# MSPM0G350X register map
Vendor: Texas Instruments; File version: This preliminary header file does not have a version number - build date: 2023-02-21 16:25:48
CPU: CM0 r0p1, little endian, MPU, no FPU, 3 interrupt priority bits
Registers are 32-bit, read-write, reset 0x0 unless marked. A register's access mark holds for its fields unless they carry their own. Offsets are from the block's base; [hi:lo] are bit positions; {n}, {i} and the like mark numbered series.

## SYSCTL — mem_map
Base 0x400AF000
0x1020 IIDX ro — SYSCTL interrupt index
  [3:0] IIDX_STAT — The SYSCTL interrupt index (IIDX) register generates a value corresponding to the highest priority pending interrupt source. This value may be used as an address offset for fast, deterministic handling in the interrupt service routine. A read of the IIDX register will clear the corresponding interrupt status in the RIS and MIS registers.
    0=IIDX_STAT_NO_INTR (NO_INTR); 1=IIDX_STAT_LFOSCGOOD (LFOSCGOOD); 2=IIDX_STAT_ANACLKERR (ANACLKERR); 3=IIDX_STAT_FLASHSEC (FLASHSEC); 4=IIDX_STAT_SRAMSEC (SRAMSEC); 5=IIDX_STAT_LFXTGOOD (LFXTGOOD); 6=IIDX_STAT_HFCLKGOOD (HFCLKGOOD); 7=IIDX_STAT_SYSPLLGOOD (SYSPLLGOOD); 8=IIDX_STAT_HSCLKGOOD (HSCLKGOOD)
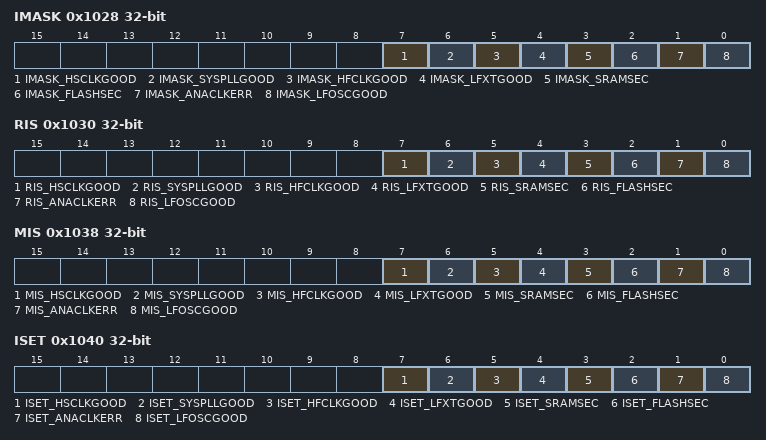
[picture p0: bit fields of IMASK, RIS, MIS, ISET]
0x1028 IMASK — SYSCTL interrupt mask
  [7] IMASK_HSCLKGOOD — HSCLK GOOD
    0=IMASK_HSCLKGOOD_DISABLE (DISABLE); 1=IMASK_HSCLKGOOD_ENABLE (ENABLE)
  [6] IMASK_SYSPLLGOOD — SYSPLL GOOD
    0=IMASK_SYSPLLGOOD_DISABLE (DISABLE); 1=IMASK_SYSPLLGOOD_ENABLE (ENABLE)
  [5] IMASK_HFCLKGOOD — HFCLK GOOD
    0=IMASK_HFCLKGOOD_DISABLE (DISABLE); 1=IMASK_HFCLKGOOD_ENABLE (ENABLE)
  [4] IMASK_LFXTGOOD — LFXT GOOD
    0=IMASK_LFXTGOOD_DISABLE (DISABLE); 1=IMASK_LFXTGOOD_ENABLE (ENABLE)
  [3] IMASK_SRAMSEC — SRAM Single Error Correct
    0=IMASK_SRAMSEC_DISABLE (DISABLE); 1=IMASK_SRAMSEC_ENABLE (ENABLE)
  [2] IMASK_FLASHSEC — Flash Single Error Correct
    0=IMASK_FLASHSEC_DISABLE (DISABLE); 1=IMASK_FLASHSEC_ENABLE (ENABLE)
  [1] IMASK_ANACLKERR — Analog Clocking Consistency Error
    0=IMASK_ANACLKERR_DISABLE (DISABLE); 1=IMASK_ANACLKERR_ENABLE (ENABLE)
  [0] IMASK_LFOSCGOOD — Enable or disable the LFOSCGOOD interrupt. LFOSCGOOD indicates that the LFOSC has started successfully.
    0=IMASK_LFOSCGOOD_DISABLE (DISABLE); 1=IMASK_LFOSCGOOD_ENABLE (ENABLE)
0x1030 RIS ro — SYSCTL raw interrupt status
  [7] RIS_HSCLKGOOD — HSCLK GOOD
    0=RIS_HSCLKGOOD_FALSE (FALSE); 1=RIS_HSCLKGOOD_TRUE (TRUE)
  [6] RIS_SYSPLLGOOD — SYSPLL GOOD
    0=RIS_SYSPLLGOOD_FALSE (FALSE); 1=RIS_SYSPLLGOOD_TRUE (TRUE)
  [5] RIS_HFCLKGOOD — HFCLK GOOD
    0=RIS_HFCLKGOOD_FALSE (FALSE); 1=RIS_HFCLKGOOD_TRUE (TRUE)
  [4] RIS_LFXTGOOD — LFXT GOOD
    0=RIS_LFXTGOOD_FALSE (FALSE); 1=RIS_LFXTGOOD_TRUE (TRUE)
  [3] RIS_SRAMSEC — SRAM Single Error Correct
    0=RIS_SRAMSEC_FALSE (FALSE); 1=RIS_SRAMSEC_TRUE (TRUE)
  [2] RIS_FLASHSEC — Flash Single Error Correct
    0=RIS_FLASHSEC_FALSE (FALSE); 1=RIS_FLASHSEC_TRUE (TRUE)
  [1] RIS_ANACLKERR — Analog Clocking Consistency Error
    0=RIS_ANACLKERR_FALSE (FALSE); 1=RIS_ANACLKERR_TRUE (TRUE)
  [0] RIS_LFOSCGOOD — Raw status of the LFOSCGOOD interrupt.
    0=RIS_LFOSCGOOD_FALSE (FALSE); 1=RIS_LFOSCGOOD_TRUE (TRUE)
0x1038 MIS ro — SYSCTL masked interrupt status
  [7] MIS_HSCLKGOOD — HSCLK GOOD
    0=MIS_HSCLKGOOD_FALSE (FALSE); 1=MIS_HSCLKGOOD_TRUE (TRUE)
  [6] MIS_SYSPLLGOOD — SYSPLL GOOD
    0=MIS_SYSPLLGOOD_FALSE (FALSE); 1=MIS_SYSPLLGOOD_TRUE (TRUE)
  [5] MIS_HFCLKGOOD — HFCLK GOOD
    0=MIS_HFCLKGOOD_FALSE (FALSE); 1=MIS_HFCLKGOOD_TRUE (TRUE)
  [4] MIS_LFXTGOOD — LFXT GOOD
    0=MIS_LFXTGOOD_FALSE (FALSE); 1=MIS_LFXTGOOD_TRUE (TRUE)
  [3] MIS_SRAMSEC — SRAM Single Error Correct
    0=MIS_SRAMSEC_FALSE (FALSE); 1=MIS_SRAMSEC_TRUE (TRUE)
  [2] MIS_FLASHSEC — Flash Single Error Correct
    0=MIS_FLASHSEC_FALSE (FALSE); 1=MIS_FLASHSEC_TRUE (TRUE)
  [1] MIS_ANACLKERR — Analog Clocking Consistency Error
    0=MIS_ANACLKERR_FALSE (FALSE); 1=MIS_ANACLKERR_TRUE (TRUE)
  [0] MIS_LFOSCGOOD — Masked status of the LFOSCGOOD interrupt.
    0=MIS_LFOSCGOOD_FALSE (FALSE); 1=MIS_LFOSCGOOD_TRUE (TRUE)
0x1040 ISET wo — SYSCTL interrupt set
  [7] ISET_HSCLKGOOD — HSCLK GOOD
    0=ISET_HSCLKGOOD_NO_EFFECT (NO_EFFECT); 1=ISET_HSCLKGOOD_SET (SET)
  [6] ISET_SYSPLLGOOD — SYSPLL GOOD
    0=ISET_SYSPLLGOOD_NO_EFFECT (NO_EFFECT); 1=ISET_SYSPLLGOOD_SET (SET)
  [5] ISET_HFCLKGOOD — HFCLK GOOD
    0=ISET_HFCLKGOOD_NO_EFFECT (NO_EFFECT); 1=ISET_HFCLKGOOD_SET (SET)
  [4] ISET_LFXTGOOD — LFXT GOOD
    0=ISET_LFXTGOOD_NO_EFFECT (NO_EFFECT); 1=ISET_LFXTGOOD_SET (SET)
  [3] ISET_SRAMSEC — SRAM Single Error Correct
    0=ISET_SRAMSEC_NO_EFFECT (NO_EFFECT); 1=ISET_SRAMSEC_SET (SET)
  [2] ISET_FLASHSEC — Flash Single Error Correct
    0=ISET_FLASHSEC_NO_EFFECT (NO_EFFECT); 1=ISET_FLASHSEC_SET (SET)
  [1] ISET_ANACLKERR — Analog Clocking Consistency Error
    0=ISET_ANACLKERR_NO_EFFECT (NO_EFFECT); 1=ISET_ANACLKERR_SET (SET)
  [0] ISET_LFOSCGOOD — Set the LFOSCGOOD interrupt.
    0=ISET_LFOSCGOOD_NO_EFFECT (NO_EFFECT); 1=ISET_LFOSCGOOD_SET (SET)
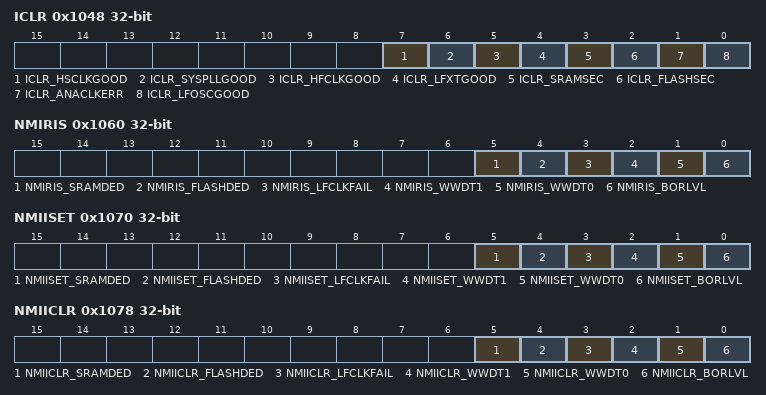
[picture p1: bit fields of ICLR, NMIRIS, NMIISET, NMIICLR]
0x1048 ICLR wo — SYSCTL interrupt clear
  [7] ICLR_HSCLKGOOD — HSCLK GOOD
    0=ICLR_HSCLKGOOD_NO_EFFECT (NO_EFFECT); 1=ICLR_HSCLKGOOD_CLR (CLR)
  [6] ICLR_SYSPLLGOOD — SYSPLL GOOD
    0=ICLR_SYSPLLGOOD_NO_EFFECT (NO_EFFECT); 1=ICLR_SYSPLLGOOD_CLR (CLR)
  [5] ICLR_HFCLKGOOD — HFCLK GOOD
    0=ICLR_HFCLKGOOD_NO_EFFECT (NO_EFFECT); 1=ICLR_HFCLKGOOD_CLR (CLR)
  [4] ICLR_LFXTGOOD — LFXT GOOD
    0=ICLR_LFXTGOOD_NO_EFFECT (NO_EFFECT); 1=ICLR_LFXTGOOD_CLR (CLR)
  [3] ICLR_SRAMSEC — SRAM Single Error Correct
    0=ICLR_SRAMSEC_NO_EFFECT (NO_EFFECT); 1=ICLR_SRAMSEC_CLR (CLR)
  [2] ICLR_FLASHSEC — Flash Single Error Correct
    0=ICLR_FLASHSEC_NO_EFFECT (NO_EFFECT); 1=ICLR_FLASHSEC_CLR (CLR)
  [1] ICLR_ANACLKERR — Analog Clocking Consistency Error
    0=ICLR_ANACLKERR_NO_EFFECT (NO_EFFECT); 1=ICLR_ANACLKERR_CLR (CLR)
  [0] ICLR_LFOSCGOOD — Clear the LFOSCGOOD interrupt.
    0=ICLR_LFOSCGOOD_NO_EFFECT (NO_EFFECT); 1=ICLR_LFOSCGOOD_CLR (CLR)
0x1050 NMIIIDX ro — NMI interrupt index
  [3:0] NMIIIDX_STAT — The NMI interrupt index (NMIIIDX) register generates a value corresponding to the highest priority pending NMI source. This value may be used as an address offset for fast, deterministic handling in the NMI service routine. A read of the NMIIIDX register will clear the corresponding interrupt status in the NMIRIS register.
    0=NMIIIDX_STAT_NO_INTR (NO_INTR); 1=NMIIIDX_STAT_BORLVL (BORLVL); 2=NMIIIDX_STAT_WWDT0 (WWDT0); 3=NMIIIDX_STAT_WWDT1 (WWDT1); 4=NMIIIDX_STAT_LFCLKFAIL (LFCLKFAIL); 5=NMIIIDX_STAT_FLASHDED (FLASHDED); 6=NMIIIDX_STAT_SRAMDED (SRAMDED)
0x1060 NMIRIS ro — NMI raw interrupt status
  [5] NMIRIS_SRAMDED — SRAM Double Error Detect
    0=NMIRIS_SRAMDED_FALSE (FALSE); 1=NMIRIS_SRAMDED_TRUE (TRUE)
  [4] NMIRIS_FLASHDED — Flash Double Error Detect
    0=NMIRIS_FLASHDED_FALSE (FALSE); 1=NMIRIS_FLASHDED_TRUE (TRUE)
  [3] NMIRIS_LFCLKFAIL — LFXT-EXLF Monitor Fail
    0=NMIRIS_LFCLKFAIL_FALSE (FALSE); 1=NMIRIS_LFCLKFAIL_TRUE (TRUE)
  [2] NMIRIS_WWDT1 — Watch Dog 0 Fault
    0=NMIRIS_WWDT1_FALSE (FALSE); 1=NMIRIS_WWDT1_TRUE (TRUE)
  [1] NMIRIS_WWDT0 — Watch Dog 0 Fault
    0=NMIRIS_WWDT0_FALSE (FALSE); 1=NMIRIS_WWDT0_TRUE (TRUE)
  [0] NMIRIS_BORLVL — Raw status of the BORLVL NMI
    0=NMIRIS_BORLVL_FALSE (FALSE); 1=NMIRIS_BORLVL_TRUE (TRUE)
0x1070 NMIISET wo — NMI interrupt set
  [5] NMIISET_SRAMDED — SRAM Double Error Detect
    0=NMIISET_SRAMDED_NO_EFFECT (NO_EFFECT); 1=NMIISET_SRAMDED_SET (SET)
  [4] NMIISET_FLASHDED — Flash Double Error Detect
    0=NMIISET_FLASHDED_NO_EFFECT (NO_EFFECT); 1=NMIISET_FLASHDED_SET (SET)
  [3] NMIISET_LFCLKFAIL — LFXT-EXLF Monitor Fail
    0=NMIISET_LFCLKFAIL_NO_EFFECT (NO_EFFECT); 1=NMIISET_LFCLKFAIL_SET (SET)
  [2] NMIISET_WWDT1 — Watch Dog 0 Fault
    0=NMIISET_WWDT1_NO_EFFECT (NO_EFFECT); 1=NMIISET_WWDT1_SET (SET)
  [1] NMIISET_WWDT0 — Watch Dog 0 Fault
    0=NMIISET_WWDT0_NO_EFFECT (NO_EFFECT); 1=NMIISET_WWDT0_SET (SET)
  [0] NMIISET_BORLVL — Set the BORLVL NMI
    0=NMIISET_BORLVL_NO_EFFECT (NO_EFFECT); 1=NMIISET_BORLVL_SET (SET)
0x1078 NMIICLR wo — NMI interrupt clear
  [5] NMIICLR_SRAMDED — SRAM Double Error Detect
    0=NMIICLR_SRAMDED_NO_EFFECT (NO_EFFECT); 1=NMIICLR_SRAMDED_CLR (CLR)
  [4] NMIICLR_FLASHDED — Flash Double Error Detect
    0=NMIICLR_FLASHDED_NO_EFFECT (NO_EFFECT); 1=NMIICLR_FLASHDED_CLR (CLR)
  [3] NMIICLR_LFCLKFAIL — LFXT-EXLF Monitor Fail
    0=NMIICLR_LFCLKFAIL_NO_EFFECT (NO_EFFECT); 1=NMIICLR_LFCLKFAIL_CLR (CLR)
  [2] NMIICLR_WWDT1 — Watch Dog 0 Fault
    0=NMIICLR_WWDT1_NO_EFFECT (NO_EFFECT); 1=NMIICLR_WWDT1_CLR (CLR)
  [1] NMIICLR_WWDT0 — Watch Dog 0 Fault
    0=NMIICLR_WWDT0_NO_EFFECT (NO_EFFECT); 1=NMIICLR_WWDT0_CLR (CLR)
  [0] NMIICLR_BORLVL — Clr the BORLVL NMI
    0=NMIICLR_BORLVL_NO_EFFECT (NO_EFFECT); 1=NMIICLR_BORLVL_CLR (CLR)
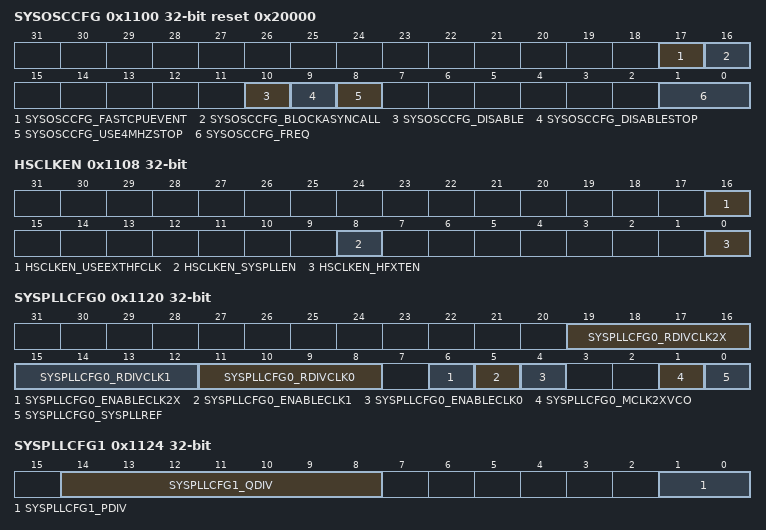
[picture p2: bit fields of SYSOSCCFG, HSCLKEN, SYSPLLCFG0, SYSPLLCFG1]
0x1100 SYSOSCCFG reset 0x20000 — SYSOSC configuration
  [17] SYSOSCCFG_FASTCPUEVENT — FASTCPUEVENT may be used to assert a fast clock request when an interrupt is asserted to the CPU, reducing interrupt latency.
    0=SYSOSCCFG_FASTCPUEVENT_DISABLE (DISABLE); 1=SYSOSCCFG_FASTCPUEVENT_ENABLE (ENABLE)
  [16] SYSOSCCFG_BLOCKASYNCALL — BLOCKASYNCALL may be used to mask block all asynchronous fast clock requests, preventing hardware from dynamically changing the active clock configuration when operating in a given mode.
    0=SYSOSCCFG_BLOCKASYNCALL_DISABLE (DISABLE); 1=SYSOSCCFG_BLOCKASYNCALL_ENABLE (ENABLE)
  [10] SYSOSCCFG_DISABLE — DISABLE sets the SYSOSC enable/disable policy. SYSOSC may be powered off in RUN, SLEEP, and STOP modes to reduce power consumption. When SYSOSC is disabled, MCLK and ULPCLK are sourced from LFCLK.
    0=SYSOSCCFG_DISABLE_DISABLE (DISABLE); 1=SYSOSCCFG_DISABLE_ENABLE (ENABLE)
  [9] SYSOSCCFG_DISABLESTOP — DISABLESTOP sets the SYSOSC stop mode enable/disable policy. When operating in STOP mode, the SYSOSC may be automatically disabled. When set, ULPCLK will run from LFCLK in STOP mode and SYSOSC will be disabled to reduce power consumption.
    0=SYSOSCCFG_DISABLESTOP_DISABLE (DISABLE); 1=SYSOSCCFG_DISABLESTOP_ENABLE (ENABLE)
  [8] SYSOSCCFG_USE4MHZSTOP — USE4MHZSTOP sets the SYSOSC stop mode frequency policy. When entering STOP mode, the SYSOSC frequency may be automatically switched to 4MHz to reduce SYSOSC power consumption.
    0=SYSOSCCFG_USE4MHZSTOP_DISABLE (DISABLE); 1=SYSOSCCFG_USE4MHZSTOP_ENABLE (ENABLE)
  [1:0] SYSOSCCFG_FREQ — Target operating frequency for the system oscillator (SYSOSC)
    0=SYSOSCCFG_FREQ_SYSOSCBASE (SYSOSCBASE); 1=SYSOSCCFG_FREQ_SYSOSC4M (SYSOSC4M); 2=SYSOSCCFG_FREQ_SYSOSCUSER (SYSOSCUSER)
0x1108 HSCLKEN — High-speed clock (HSCLK) source enable/disable
  [16] HSCLKEN_USEEXTHFCLK — USEEXTHFCLK selects the HFCLK_IN digital clock input to be the source for HFCLK. When disabled, HFXT is the HFCLK source and HFXTEN may be set. Do not set HFXTEN and USEEXTHFCLK simultaneously.
    0=HSCLKEN_USEEXTHFCLK_DISABLE (DISABLE); 1=HSCLKEN_USEEXTHFCLK_ENABLE (ENABLE)
  [8] HSCLKEN_SYSPLLEN — SYSPLLEN enables or disables the system phase-lock loop (SYSPLL).
    0=HSCLKEN_SYSPLLEN_DISABLE (DISABLE); 1=HSCLKEN_SYSPLLEN_ENABLE (ENABLE)
  [0] HSCLKEN_HFXTEN — HFXTEN enables or disables the high frequency crystal oscillator (HFXT).
    0=HSCLKEN_HFXTEN_DISABLE (DISABLE); 1=HSCLKEN_HFXTEN_ENABLE (ENABLE)
0x1120 SYSPLLCFG0 — SYSPLL reference and output configuration
  [19:16] SYSPLLCFG0_RDIVCLK2X — RDIVCLK2X sets the final divider for the SYSPLLCLK2X output.
    {v}=SYSPLLCFG0_RDIVCLK2X_CLK2XDIV{v+1} (CLK2XDIV{v+1}) (v=0..15)
  [15:12] SYSPLLCFG0_RDIVCLK1 — RDIVCLK1 sets the final divider for the SYSPLLCLK1 output.
    0=SYSPLLCFG0_RDIVCLK1_CLK1DIV2 (CLK1DIV2); 1=SYSPLLCFG0_RDIVCLK1_CLK1DIV4 (CLK1DIV4); 2=SYSPLLCFG0_RDIVCLK1_CLK1DIV6 (CLK1DIV6); 3=SYSPLLCFG0_RDIVCLK1_CLK1DIV8 (CLK1DIV8); 4=SYSPLLCFG0_RDIVCLK1_CLK1DIV10 (CLK1DIV10); 5=SYSPLLCFG0_RDIVCLK1_CLK1DIV12 (CLK1DIV12); 6=SYSPLLCFG0_RDIVCLK1_CLK1DIV14 (CLK1DIV14); 7=SYSPLLCFG0_RDIVCLK1_CLK1DIV16 (CLK1DIV16); 8=SYSPLLCFG0_RDIVCLK1_CLK1DIV18 (CLK1DIV18); 9=SYSPLLCFG0_RDIVCLK1_CLK1DIV20 (CLK1DIV20); 10=SYSPLLCFG0_RDIVCLK1_CLK1DIV22 (CLK1DIV22); 11=SYSPLLCFG0_RDIVCLK1_CLK1DIV24 (CLK1DIV24); 12=SYSPLLCFG0_RDIVCLK1_CLK1DIV26 (CLK1DIV26); 13=SYSPLLCFG0_RDIVCLK1_CLK1DIV28 (CLK1DIV28); 14=SYSPLLCFG0_RDIVCLK1_CLK1DIV30 (CLK1DIV30); 15=SYSPLLCFG0_RDIVCLK1_CLK1DIV32 (CLK1DIV32)
  [11:8] SYSPLLCFG0_RDIVCLK0 — RDIVCLK0 sets the final divider for the SYSPLLCLK0 output.
    0=SYSPLLCFG0_RDIVCLK0_CLK0DIV2 (CLK0DIV2); 1=SYSPLLCFG0_RDIVCLK0_CLK0DIV4 (CLK0DIV4); 2=SYSPLLCFG0_RDIVCLK0_CLK0DIV6 (CLK0DIV6); 3=SYSPLLCFG0_RDIVCLK0_CLK0DIV8 (CLK0DIV8); 4=SYSPLLCFG0_RDIVCLK0_CLK0DIV10 (CLK0DIV10); 5=SYSPLLCFG0_RDIVCLK0_CLK0DIV12 (CLK0DIV12); 6=SYSPLLCFG0_RDIVCLK0_CLK0DIV14 (CLK0DIV14); 7=SYSPLLCFG0_RDIVCLK0_CLK0DIV16 (CLK0DIV16); 8=SYSPLLCFG0_RDIVCLK0_CLK0DIV18 (CLK0DIV18); 9=SYSPLLCFG0_RDIVCLK0_CLK0DIV20 (CLK0DIV20); 10=SYSPLLCFG0_RDIVCLK0_CLK0DIV22 (CLK0DIV22); 11=SYSPLLCFG0_RDIVCLK0_CLK0DIV24 (CLK0DIV24); 12=SYSPLLCFG0_RDIVCLK0_CLK0DIV26 (CLK0DIV26); 13=SYSPLLCFG0_RDIVCLK0_CLK0DIV28 (CLK0DIV28); 14=SYSPLLCFG0_RDIVCLK0_CLK0DIV30 (CLK0DIV30); 15=SYSPLLCFG0_RDIVCLK0_CLK0DIV32 (CLK0DIV32)
  [6] SYSPLLCFG0_ENABLECLK2X — ENABLECLK2X enables or disables the SYSPLLCLK2X output.
    0=SYSPLLCFG0_ENABLECLK2X_DISABLE (DISABLE); 1=SYSPLLCFG0_ENABLECLK2X_ENABLE (ENABLE)
  [5] SYSPLLCFG0_ENABLECLK1 — ENABLECLK1 enables or disables the SYSPLLCLK1 output.
    0=SYSPLLCFG0_ENABLECLK1_DISABLE (DISABLE); 1=SYSPLLCFG0_ENABLECLK1_ENABLE (ENABLE)
  [4] SYSPLLCFG0_ENABLECLK0 — ENABLECLK0 enables or disables the SYSPLLCLK0 output.
    0=SYSPLLCFG0_ENABLECLK0_DISABLE (DISABLE); 1=SYSPLLCFG0_ENABLECLK0_ENABLE (ENABLE)
  [1] SYSPLLCFG0_MCLK2XVCO — MCLK2XVCO selects the SYSPLL output which is sent to the HSCLK mux for use by MCLK.
    0=SYSPLLCFG0_MCLK2XVCO_DISABLE (DISABLE); 1=SYSPLLCFG0_MCLK2XVCO_ENABLE (ENABLE)
  [0] SYSPLLCFG0_SYSPLLREF — SYSPLLREF selects the system PLL (SYSPLL) reference clock source.
    0=SYSPLLCFG0_SYSPLLREF_SYSOSC (SYSOSC); 1=SYSPLLCFG0_SYSPLLREF_HFCLK (HFCLK)
0x1124 SYSPLLCFG1 — SYSPLL reference and feedback divider
  [14:8] SYSPLLCFG1_QDIV — QDIV selects the SYSPLL feedback path divider.
    0=SYSPLLCFG1_QDIV_INVALID (INVALID); 1=SYSPLLCFG1_QDIV_QDIVMIN (QDIVMIN); 126=SYSPLLCFG1_QDIV_QDIVMAX (QDIVMAX)
  [1:0] SYSPLLCFG1_PDIV — PDIV selects the SYSPLL reference clock prescale divider.
    0=SYSPLLCFG1_PDIV_REFDIV1 (REFDIV1); 1=SYSPLLCFG1_PDIV_REFDIV2 (REFDIV2); 2=SYSPLLCFG1_PDIV_REFDIV4 (REFDIV4); 3=SYSPLLCFG1_PDIV_REFDIV8 (REFDIV8)
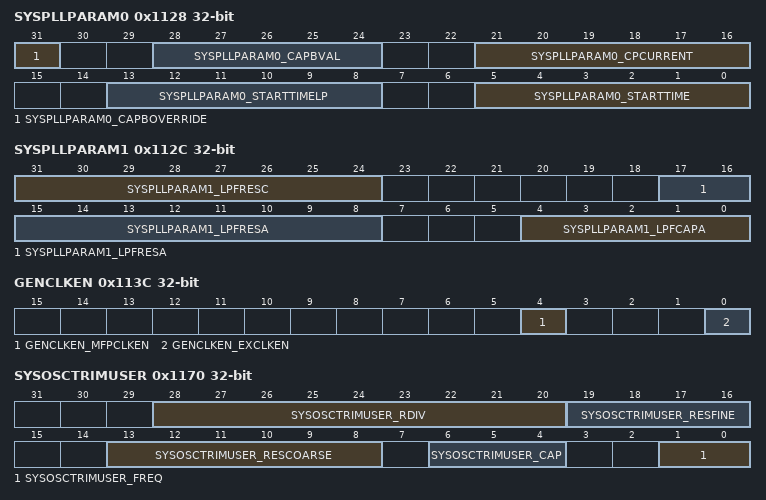
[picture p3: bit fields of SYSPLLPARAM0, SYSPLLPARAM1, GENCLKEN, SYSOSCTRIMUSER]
0x1128 SYSPLLPARAM0 — SYSPLL PARAM0 (load from FACTORY region)
  [31] SYSPLLPARAM0_CAPBOVERRIDE — CAPBOVERRIDE controls the override for Cap B
    0=SYSPLLPARAM0_CAPBOVERRIDE_DISABLE (DISABLE); 1=SYSPLLPARAM0_CAPBOVERRIDE_ENABLE (ENABLE)
  [28:24] SYSPLLPARAM0_CAPBVAL — Override value for Cap B
  [21:16] SYSPLLPARAM0_CPCURRENT — Charge pump current
  [13:8] SYSPLLPARAM0_STARTTIMELP — Startup time from low power mode exit to locked clock, in 1us resolution
  [5:0] SYSPLLPARAM0_STARTTIME — Startup time from enable to locked clock, in 1us resolution
0x112C SYSPLLPARAM1 — SYSPLL PARAM1 (load from FACTORY region)
  [31:24] SYSPLLPARAM1_LPFRESC — Loop filter Res C
  [17:8] SYSPLLPARAM1_LPFRESA — Loop filter Res A
  [4:0] SYSPLLPARAM1_LPFCAPA — Loop filter Cap A
0x113C GENCLKEN — General clock enable control
  [4] GENCLKEN_MFPCLKEN — MFPCLKEN enables the middle frequency precision clock (MFPCLK).
    0=GENCLKEN_MFPCLKEN_DISABLE (DISABLE); 1=GENCLKEN_MFPCLKEN_ENABLE (ENABLE)
  [0] GENCLKEN_EXCLKEN — EXCLKEN enables the CLK_OUT external clock output block.
    0=GENCLKEN_EXCLKEN_DISABLE (DISABLE); 1=GENCLKEN_EXCLKEN_ENABLE (ENABLE)
0x1140 PMODECFG — Power mode configuration
  [1:0] PMODECFG_DSLEEP — DSLEEP selects the operating mode to enter upon a DEEPSLEEP request from the CPU.
    0=PMODECFG_DSLEEP_STOP (STOP); 1=PMODECFG_DSLEEP_STANDBY (STANDBY); 2=PMODECFG_DSLEEP_SHUTDOWN (SHUTDOWN)
0x1150 FCC ro — Frequency clock counter (FCC) count
  [21:0] FCC_DATA — Frequency clock counter (FCC) count value.
0x1170 SYSOSCTRIMUSER — SYSOSC user-specified trim
  [28:20] SYSOSCTRIMUSER_RDIV — RDIV specifies the frequency correction loop (FCL) resistor trim. This value changes with the target frequency.
  [19:16] SYSOSCTRIMUSER_RESFINE — RESFINE specifies the resister fine trim. This value changes with the target frequency.
  [13:8] SYSOSCTRIMUSER_RESCOARSE — RESCOARSE specifies the resister coarse trim. This value changes with the target frequency.
  [6:4] SYSOSCTRIMUSER_CAP — CAP specifies the SYSOSC capacitor trim. This value changes with the target frequency.
  [1:0] SYSOSCTRIMUSER_FREQ — FREQ specifies the target user-trimmed frequency for SYSOSC.
    1=SYSOSCTRIMUSER_FREQ_SYSOSC16M (SYSOSC16M); 2=SYSOSCTRIMUSER_FREQ_SYSOSC24M (SYSOSC24M)
0x1178 SRAMBOUNDARY — SRAM Write Boundary
  [19:5] SRAMBOUNDARY_ADDR — SRAM boundary configuration. The value configured into this acts such that: SRAM accesses to addresses less than or equal value will be RW only. SRAM accesses to addresses greater than value will be RX only. Value of 0 is not valid (system will have no stack). If set to 0, the system acts as if the entire SRAM is RWX. Any non-zero value can be configured, including a value = SRAM size.
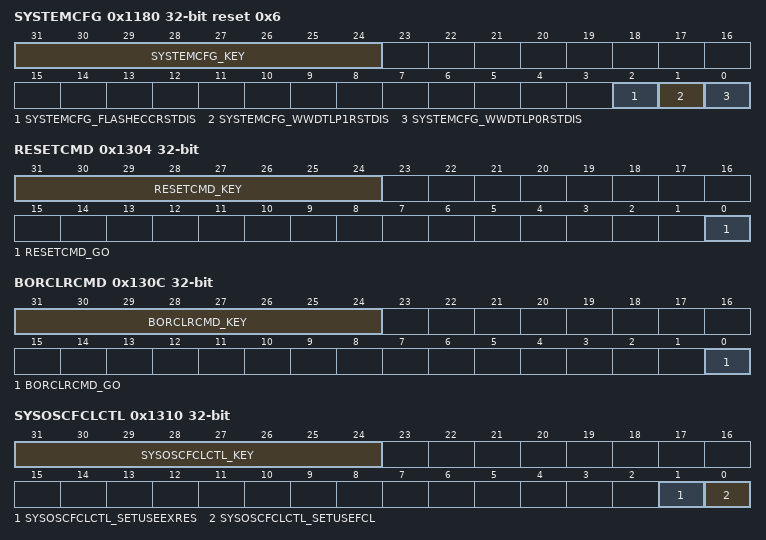
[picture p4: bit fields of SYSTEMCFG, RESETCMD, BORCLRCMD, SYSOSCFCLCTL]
0x1180 SYSTEMCFG reset 0x6 — System configuration
  [31:24] SYSTEMCFG_KEY wo — The key value of 1Bh (27) must be written to KEY together with contents to be updated. Reads as 0
    27=SYSTEMCFG_KEY_VALUE (VALUE)
  [2] SYSTEMCFG_FLASHECCRSTDIS — FLASHECCRSTDIS specifies whether a flash ECC double error detect (DED) will trigger a SYSRST or an NMI.
    0=SYSTEMCFG_FLASHECCRSTDIS_FALSE (FALSE); 1=SYSTEMCFG_FLASHECCRSTDIS_TRUE (TRUE)
  [1] SYSTEMCFG_WWDTLP1RSTDIS — WWDTLP1RSTDIS specifies whether a WWDT Error Event will trigger a SYSRST or an NMI.
    0=SYSTEMCFG_WWDTLP1RSTDIS_FALSE (FALSE); 1=SYSTEMCFG_WWDTLP1RSTDIS_TRUE (TRUE)
  [0] SYSTEMCFG_WWDTLP0RSTDIS — WWDTLP0RSTDIS specifies whether a WWDT Error Event will trigger a BOOTRST or an NMI.
    0=SYSTEMCFG_WWDTLP0RSTDIS_FALSE (FALSE); 1=SYSTEMCFG_WWDTLP0RSTDIS_TRUE (TRUE)
0x1200 WRITELOCK — SYSCTL register write lockout
  [0] WRITELOCK_ACTIVE — ACTIVE controls whether critical SYSCTL registers are write protected or not.
    0=WRITELOCK_ACTIVE_DISABLE (DISABLE); 1=WRITELOCK_ACTIVE_ENABLE (ENABLE)
0x120C DEDERRADDR ro — Memory DED Address
  [31:0] DEDERRADDR_ADDR — Address of MEMORY DED Error.
0x1220 RSTCAUSE ro — Reset cause
  [4:0] RSTCAUSE_ID — ID is a read-to-clear field which indicates the lowest level reset cause since the last read.
    0=RSTCAUSE_ID_NORST (NORST); 1=RSTCAUSE_ID_PORHWFAIL (PORHWFAIL); 2=RSTCAUSE_ID_POREXNRST (POREXNRST); 3=RSTCAUSE_ID_PORSW (PORSW); 4=RSTCAUSE_ID_BORSUPPLY (BORSUPPLY); 5=RSTCAUSE_ID_BORWAKESHUTDN (BORWAKESHUTDN); 8=RSTCAUSE_ID_BOOTNONPMUPARITY (BOOTNONPMUPARITY); 9=RSTCAUSE_ID_BOOTCLKFAIL (BOOTCLKFAIL); 10=RSTCAUSE_ID_BOOTSW (BOOTSW); 12=RSTCAUSE_ID_BOOTEXNRST (BOOTEXNRST); 16=RSTCAUSE_ID_SYSBSLEXIT (SYSBSLEXIT); 17=RSTCAUSE_ID_SYSBSLENTRY (SYSBSLENTRY); 18=RSTCAUSE_ID_SYSWWDT0 (SYSWWDT0); 19=RSTCAUSE_ID_SYSWWDT1 (SYSWWDT1); 20=RSTCAUSE_ID_SYSFLASHECC (SYSFLASHECC); 21=RSTCAUSE_ID_SYSCPULOCK (SYSCPULOCK); 26=RSTCAUSE_ID_SYSDBG (SYSDBG); 27=RSTCAUSE_ID_SYSSW (SYSSW); 28=RSTCAUSE_ID_CPUDBG (CPUDBG); 29=RSTCAUSE_ID_CPUSW (CPUSW)
0x1300 RESETLEVEL — Reset level for application-triggered reset command
  [2:0] RESETLEVEL_LEVEL — LEVEL is used to specify the type of reset to be issued when RESETCMD is set to generate a software triggered reset.
    0=RESETLEVEL_LEVEL_CPU (CPU); 1=RESETLEVEL_LEVEL_BOOT (BOOT); 2=RESETLEVEL_LEVEL_BOOTLOADERENTRY (BOOTLOADERENTRY); 3=RESETLEVEL_LEVEL_POR (POR); 4=RESETLEVEL_LEVEL_BOOTLOADEREXIT (BOOTLOADEREXIT)
0x1304 RESETCMD wo — Execute an application-triggered reset command
  [31:24] RESETCMD_KEY — The key value of E4h (228) must be written to KEY together with GO to trigger the reset.
    228=RESETCMD_KEY_VALUE (VALUE)
  [0] RESETCMD_GO — Execute the reset specified in RESETLEVEL.LEVEL. Must be written together with the KEY.
    1=RESETCMD_GO_TRUE (TRUE)
0x1308 BORTHRESHOLD — BOR threshold selection
  [1:0] BORTHRESHOLD_LEVEL — LEVEL specifies the desired BOR threshold and BOR mode.
    0=BORTHRESHOLD_LEVEL_BORMIN (BORMIN); 1=BORTHRESHOLD_LEVEL_BORLEVEL1 (BORLEVEL1); 2=BORTHRESHOLD_LEVEL_BORLEVEL2 (BORLEVEL2); 3=BORTHRESHOLD_LEVEL_BORLEVEL3 (BORLEVEL3)
0x130C BORCLRCMD wo — Set the BOR threshold
  [31:24] BORCLRCMD_KEY — The key value of C7h (199) must be written to KEY together with GO to trigger the clear and BOR threshold change.
    199=BORCLRCMD_KEY_VALUE (VALUE)
  [0] BORCLRCMD_GO — GO clears any prior BOR violation status indications and attempts to change the active BOR mode to that specified in the LEVEL field of the BORTHRESHOLD register.
    1=BORCLRCMD_GO_TRUE (TRUE)
0x1310 SYSOSCFCLCTL wo — SYSOSC frequency correction loop (FCL) ROSC enable
  [31:24] SYSOSCFCLCTL_KEY — The key value of 2Ah (42) must be written to KEY together with SETUSEFCL to enable the FCL.
    42=SYSOSCFCLCTL_KEY_VALUE (VALUE)
  [1] SYSOSCFCLCTL_SETUSEEXRES — Set SETUSEEXRES to specify that an external resistor will be used for the FCL. An appropriate resistor must be populated on the ROSC pin. This state is locked until the next BOOTRST.
    1=SYSOSCFCLCTL_SETUSEEXRES_TRUE (TRUE)
  [0] SYSOSCFCLCTL_SETUSEFCL — Set SETUSEFCL to enable the frequency correction loop in SYSOSC. Once enabled, this state is locked until the next BOOTRST.
    1=SYSOSCFCLCTL_SETUSEFCL_TRUE (TRUE)
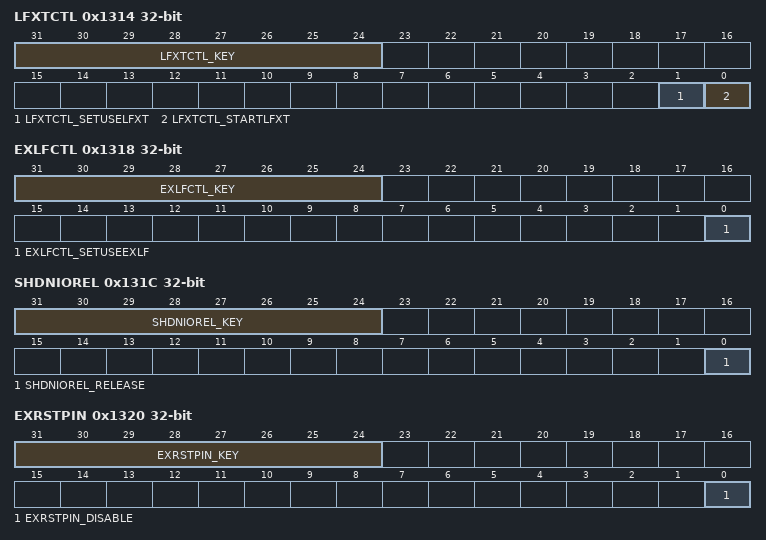
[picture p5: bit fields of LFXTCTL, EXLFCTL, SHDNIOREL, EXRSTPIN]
0x1314 LFXTCTL wo — LFXT and LFCLK control
  [31:24] LFXTCTL_KEY — The key value of 91h (145) must be written to KEY together with either STARTLFXT or SETUSELFXT to set the corresponding bit.
    145=LFXTCTL_KEY_VALUE (VALUE)
  [1] LFXTCTL_SETUSELFXT — Set SETUSELFXT to switch LFCLK to LFXT. Once set, SETUSELFXT remains set until the next BOOTRST.
    0=LFXTCTL_SETUSELFXT_FALSE (FALSE); 1=LFXTCTL_SETUSELFXT_TRUE (TRUE)
  [0] LFXTCTL_STARTLFXT — Set STARTLFXT to start the low frequency crystal oscillator (LFXT). Once set, STARTLFXT remains set until the next BOOTRST.
    0=LFXTCTL_STARTLFXT_FALSE (FALSE); 1=LFXTCTL_STARTLFXT_TRUE (TRUE)
0x1318 EXLFCTL wo — LFCLK_IN and LFCLK control
  [31:24] EXLFCTL_KEY — The key value of 36h (54) must be written to KEY together with SETUSEEXLF to set SETUSEEXLF.
    54=EXLFCTL_KEY_VALUE (VALUE)
  [0] EXLFCTL_SETUSEEXLF — Set SETUSEEXLF to switch LFCLK to the LFCLK_IN digital clock input. Once set, SETUSEEXLF remains set until the next BOOTRST.
    1=EXLFCTL_SETUSEEXLF_TRUE (TRUE)
0x131C SHDNIOREL wo — SHUTDOWN IO release control
  [31:24] SHDNIOREL_KEY — The key value 91h must be written to KEY together with RELEASE to set RELEASE.
    145=SHDNIOREL_KEY_VALUE (VALUE)
  [0] SHDNIOREL_RELEASE — Set RELEASE to release the IO after a SHUTDOWN mode exit.
    1=SHDNIOREL_RELEASE_TRUE (TRUE)
0x1320 EXRSTPIN wo — Disable the reset function of the NRST pin
  [31:24] EXRSTPIN_KEY — The key value 1Eh must be written together with DISABLE to disable the reset function.
    30=EXRSTPIN_KEY_VALUE (VALUE)
  [0] EXRSTPIN_DISABLE — Set DISABLE to disable the reset function of the NRST pin. Once set, this configuration is locked until the next POR.
    0=EXRSTPIN_DISABLE_FALSE (FALSE); 1=EXRSTPIN_DISABLE_TRUE (TRUE)
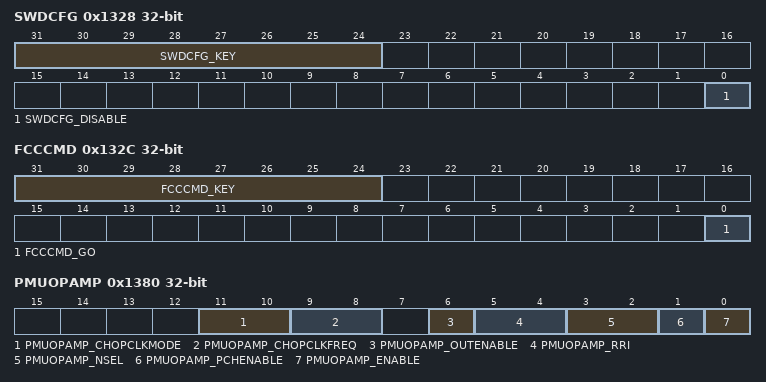
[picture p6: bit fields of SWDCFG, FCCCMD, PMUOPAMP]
0x1328 SWDCFG wo — Disable the SWD function on the SWD pins
  [31:24] SWDCFG_KEY — The key value 62h (98) must be written to KEY together with DISBALE to disable the SWD functions.
    98=SWDCFG_KEY_VALUE (VALUE)
  [0] SWDCFG_DISABLE — Set DISABLE to disable the SWD function on SWD pins, allowing the SWD pins to be used as GPIO.
    1=SWDCFG_DISABLE_TRUE (TRUE)
0x132C FCCCMD wo — Frequency clock counter start capture
  [31:24] FCCCMD_KEY — The key value 0Eh (14) must be written with GO to start a capture.
    14=FCCCMD_KEY_VALUE (VALUE)
  [0] FCCCMD_GO — Set GO to start a capture with the frequency clock counter (FCC).
    1=FCCCMD_GO_TRUE (TRUE)
0x1380 PMUOPAMP — GPAMP control
  [11:10] PMUOPAMP_CHOPCLKMODE — CHOPCLKMODE selects the GPAMP chopping mode.
    0=PMUOPAMP_CHOPCLKMODE_CHOPDISABLED (CHOPDISABLED); 1=PMUOPAMP_CHOPCLKMODE_REGCHOP (REGCHOP); 2=PMUOPAMP_CHOPCLKMODE_ADCASSIST (ADCASSIST)
  [9:8] PMUOPAMP_CHOPCLKFREQ — CHOPCLKFREQ selects the GPAMP chopping clock frequency
    0=PMUOPAMP_CHOPCLKFREQ_CLK16KHZ (CLK16KHZ); 1=PMUOPAMP_CHOPCLKFREQ_CLK8KHZ (CLK8KHZ); 2=PMUOPAMP_CHOPCLKFREQ_CLK4KHZ (CLK4KHZ); 3=PMUOPAMP_CHOPCLKFREQ_CLK2KHZ (CLK2KHZ)
  [6] PMUOPAMP_OUTENABLE — Set OUTENABLE to connect the GPAMP output signal to the GPAMP_OUT pin
    0=PMUOPAMP_OUTENABLE_FALSE (FALSE); 1=PMUOPAMP_OUTENABLE_TRUE (TRUE)
  [5:4] PMUOPAMP_RRI — RRI selects the rail-to-rail input mode.
    {v}=PMUOPAMP_RRI_MODE{v} (MODE{v}) (v=0..3)
  [3:2] PMUOPAMP_NSEL — NSEL selects the GPAMP negative channel input.
    {v}=PMUOPAMP_NSEL_SEL{v} (SEL{v}) (v=0..3)
  [1] PMUOPAMP_PCHENABLE — Set PCHENABLE to enable the positive channel input.
    0=PMUOPAMP_PCHENABLE_FALSE (FALSE); 1=PMUOPAMP_PCHENABLE_TRUE (TRUE)
  [0] PMUOPAMP_ENABLE — Set ENABLE to turn on the GPAMP.
    0=PMUOPAMP_ENABLE_FALSE (FALSE); 1=PMUOPAMP_ENABLE_TRUE (TRUE)
{0x1400+4i} SHUTDNSTORE{i} (i=0..3) — Shutdown storage memory (byte {i})
  [7:0] SHUTDNSTORE{i}_DATA — Shutdown storage byte {i}

## Notices in the file
Copyright (C) 2023 Texas Instruments Incorporated - http://www.ti.com
Redistribution and use in source and binary forms, with or without
modification, are permitted provided that the following conditions
are met:
Redistributions of source code must retain the above copyright
notice, this list of conditions and the following disclaimer.
Redistributions in binary form must reproduce the above copyright
notice, this list of conditions and the following disclaimer in the
documentation and/or other materials provided with the
distribution.
Neither the name of Texas Instruments Incorporated nor the names of
its contributors may be used to endorse or promote products derived
from this software without specific prior written permission.
THIS SOFTWARE IS PROVIDED BY THE COPYRIGHT HOLDERS AND CONTRIBUTORS
"AS IS" AND ANY EXPRESS OR IMPLIED WARRANTIES, INCLUDING, BUT NOT
LIMITED TO, THE IMPLIED WARRANTIES OF MERCHANTABILITY AND FITNESS FOR
A PARTICULAR PURPOSE ARE DISCLAIMED. IN NO EVENT SHALL THE COPYRIGHT
OWNER OR CONTRIBUTORS BE LIABLE FOR ANY DIRECT, INDIRECT, INCIDENTAL,
SPECIAL, EXEMPLARY, OR CONSEQUENTIAL DAMAGES (INCLUDING, BUT NOT
LIMITED TO, PROCUREMENT OF SUBSTITUTE GOODS OR SERVICES; LOSS OF USE,
DATA, OR PROFITS; OR BUSINESS INTERRUPTION) HOWEVER CAUSED AND ON ANY
THEORY OF LIABILITY, WHETHER IN CONTRACT, STRICT LIABILITY, OR TORT
(INCLUDING NEGLIGENCE OR OTHERWISE) ARISING IN ANY WAY OUT OF THE USE
OF THIS SOFTWARE, EVEN IF ADVISED OF THE POSSIBILITY OF SUCH DAMAGE.
